# DP32G030 register map
File version: 1.0
CPU: CM0 r0p0, little endian, no MPU, no FPU, 4 interrupt priority bits
Registers are 32-bit, read-write, reset 0x0 unless marked. A register's access mark holds for its fields unless they carry their own. Offsets are from the block's base; [hi:lo] are bit positions; {n}, {i} and the like mark numbered series.

## DMA — DMA unit
Base 0x40001000
0x00 DMA_CTR — DMA control register
  [0] DMA_EN — DMA Enable 0: DMA off 1: DMA Enable
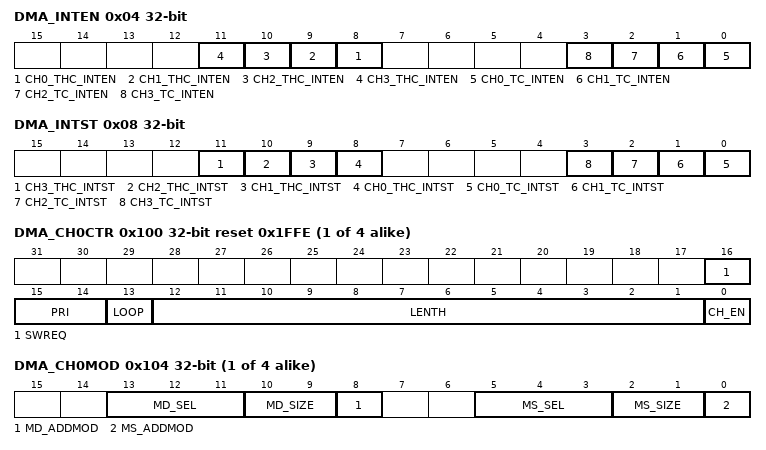
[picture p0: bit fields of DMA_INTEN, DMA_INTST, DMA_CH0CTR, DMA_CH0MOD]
0x04 DMA_INTEN — DMA interrupt enable register
  [n+8] CH{n}_THC_INTEN (n=0..3) — Channel {n} Transmission Half Completed Interrupt Enable
  [n] CH{n}_TC_INTEN (n=0..3) — Channel {n} Transmission Completion Interrupt Enable
0x08 DMA_INTST — DMA Interrupt Status Register
  [11] CH3_THC_INTST — Channel 3 Transmission Half Completed Interrupt Status Register Write 1 to clear.
  [10] CH2_THC_INTST — Channel 2 Transmission Half Completed Interrupt Status Register Write 1 to clear
  [9] CH1_THC_INTST — Channel 1 Transmission Half Completed Interrupt Status Register Write 1 to clear
  [8] CH0_THC_INTST — Channel 0 Transmission Half Completed Interrupt Status Register Write 1 to clear
  [n] CH{n}_TC_INTST (n=0..3) — Channel {n} Transmission Completion Interrupt Status Register Write 1 to clear
{0x100+0x20*i} DMA_CH{i}CTR reset 0x1FFE (i=0..3) — CH{i} control register
  [16] SWREQ — Requesting this channel to start transmission via software Write 1 Starting transmission Note 1: Only used for requests initiated when the source address side is configured as a storage device. Note 2: If LOOP is configured as 0, it will be automatically cleared by hardware upon completion of a transfer; if LOOP is configured as 1, it will be cleared by software control.
  [15:14] PRI — channel prioritization 00: Low 01: Medium 10: High 11: Maximum Note: If different channels are configured with the same priority, the one with the smaller channel number has the higher priority.
  [13] LOOP — Cycle mode control bit 0: Cyclic mode is not executed. Stop when transmission is completed 1: Execute the cyclic method. Automatically re-transmits according to the original configuration after the transmission is completed
  [12:1] LENTH — Transmission Count Register, which indicates the number of requests transmitted on this channel. The actual number of transmissions is (LENTH+1). The unit of data for each transmission is: the unit of data on the source address side is determined by the MS_SIZE is determined; the data unit on the destination address side is determined by MD_SIZE.
  [0] CH_EN — Channel Enable Control 0: Channel closed 1: Channel effective Note 1: Channel enable is written 1 by software to initiate a transmission. loop If configured as 0, a transmission is completed and automatically cleared by hardware; LOOP If configured as 1, it is cleared by software control. Note 2: All configurations need to be done with enable off. When this bit is 1, the relevant configuration cannot be changed.
{0x104+0x20*i} DMA_CH{i}MOD (i=0..3) — CH{i} mode register
  [13:11] MD_SEL — MD Side Peripheral Selection 000: Select storage peripheral 001: Select the peripheral that generates hsreq_md[0]. 010: Select the peripheral that generates hsreq_md[1]. 011: Select the peripheral that generates hsreq_md[2]. 100: Select the peripheral that generates hsreq_md[3]. 101: Select the peripheral that generates hsreq_md[4] 110: Select the peripheral that generates hsreq_md[5]. 111: Select the peripheral that generates hsreq_md[6]. Note 1: A configuration of 000 indicates the selection of a memory peripheral, usually the SRAM within the chip. It can also be used for other peripherals that are accessible without handshaking or waiting. Other peripherals that can be accessed without handshaking or waiting can also be used. Note 2: When the configuration is 001-111, the peripherals connected to different chips are different. The corresponding peripherals should be decided according to the actual peripherals connected to the specific chip.
  [10:9] MD_SIZE — MD Side Bus Transfer Width 00: 8bits 01: 16bits 10: 32bits
  [8] MD_ADDMOD — Address change method selection on the MD side 0: Address unchanged 1: Address increment
  [5:3] MS_SEL — MS Side Peripheral Selection 000: Select the memory peripheral 001: Select the peripheral that generates hsreq_ms[0]. 010: Select the peripheral that generates hsreq_ms[1]. 011: Select the peripheral that generates hsreq_ms[2]. 100: Select the peripheral that generates hsreq_ms[3]. 101: Select the peripheral that generates hsreq_ms[4]. 110: Select the peripheral that generates hsreq_ms[5]. 111: Select the peripheral that generates hsreq_ms[6]. Note 1: A configuration of 000 indicates the selection of a memory peripheral, usually the SRAM within the chip. It can also be used for other peripherals that are accessible without handshaking or waiting. Other peripherals that can be accessed without handshaking or waiting can also be used. Note 2: When the configuration is 001-111, the peripherals connected to different chips are different. The corresponding peripherals should be decided according to the actual peripherals connected to the specific chip.
  [2:1] MS_SIZE — Bus transfer width on MS side 00: 8bits 01: 16bits 10: 32bits
  [0] MS_ADDMOD — Address change method selection on the MS side 0: Address unchanged 1: Address increment
{0x108+0x20*i} DMA_CH{i}MSADDR access not given (i=0..3) — CH{i} source address register
{0x10C+0x20*i} DMA_CH{i}MDADDR access not given (i=0..3) — CH{i} Destination Address Register
{0x110+0x20*i} DMA_CH{i}_ST ro (i=0..3) — CH{i} status register
  [11:0] CUR_LENTH — Number of current transfers
